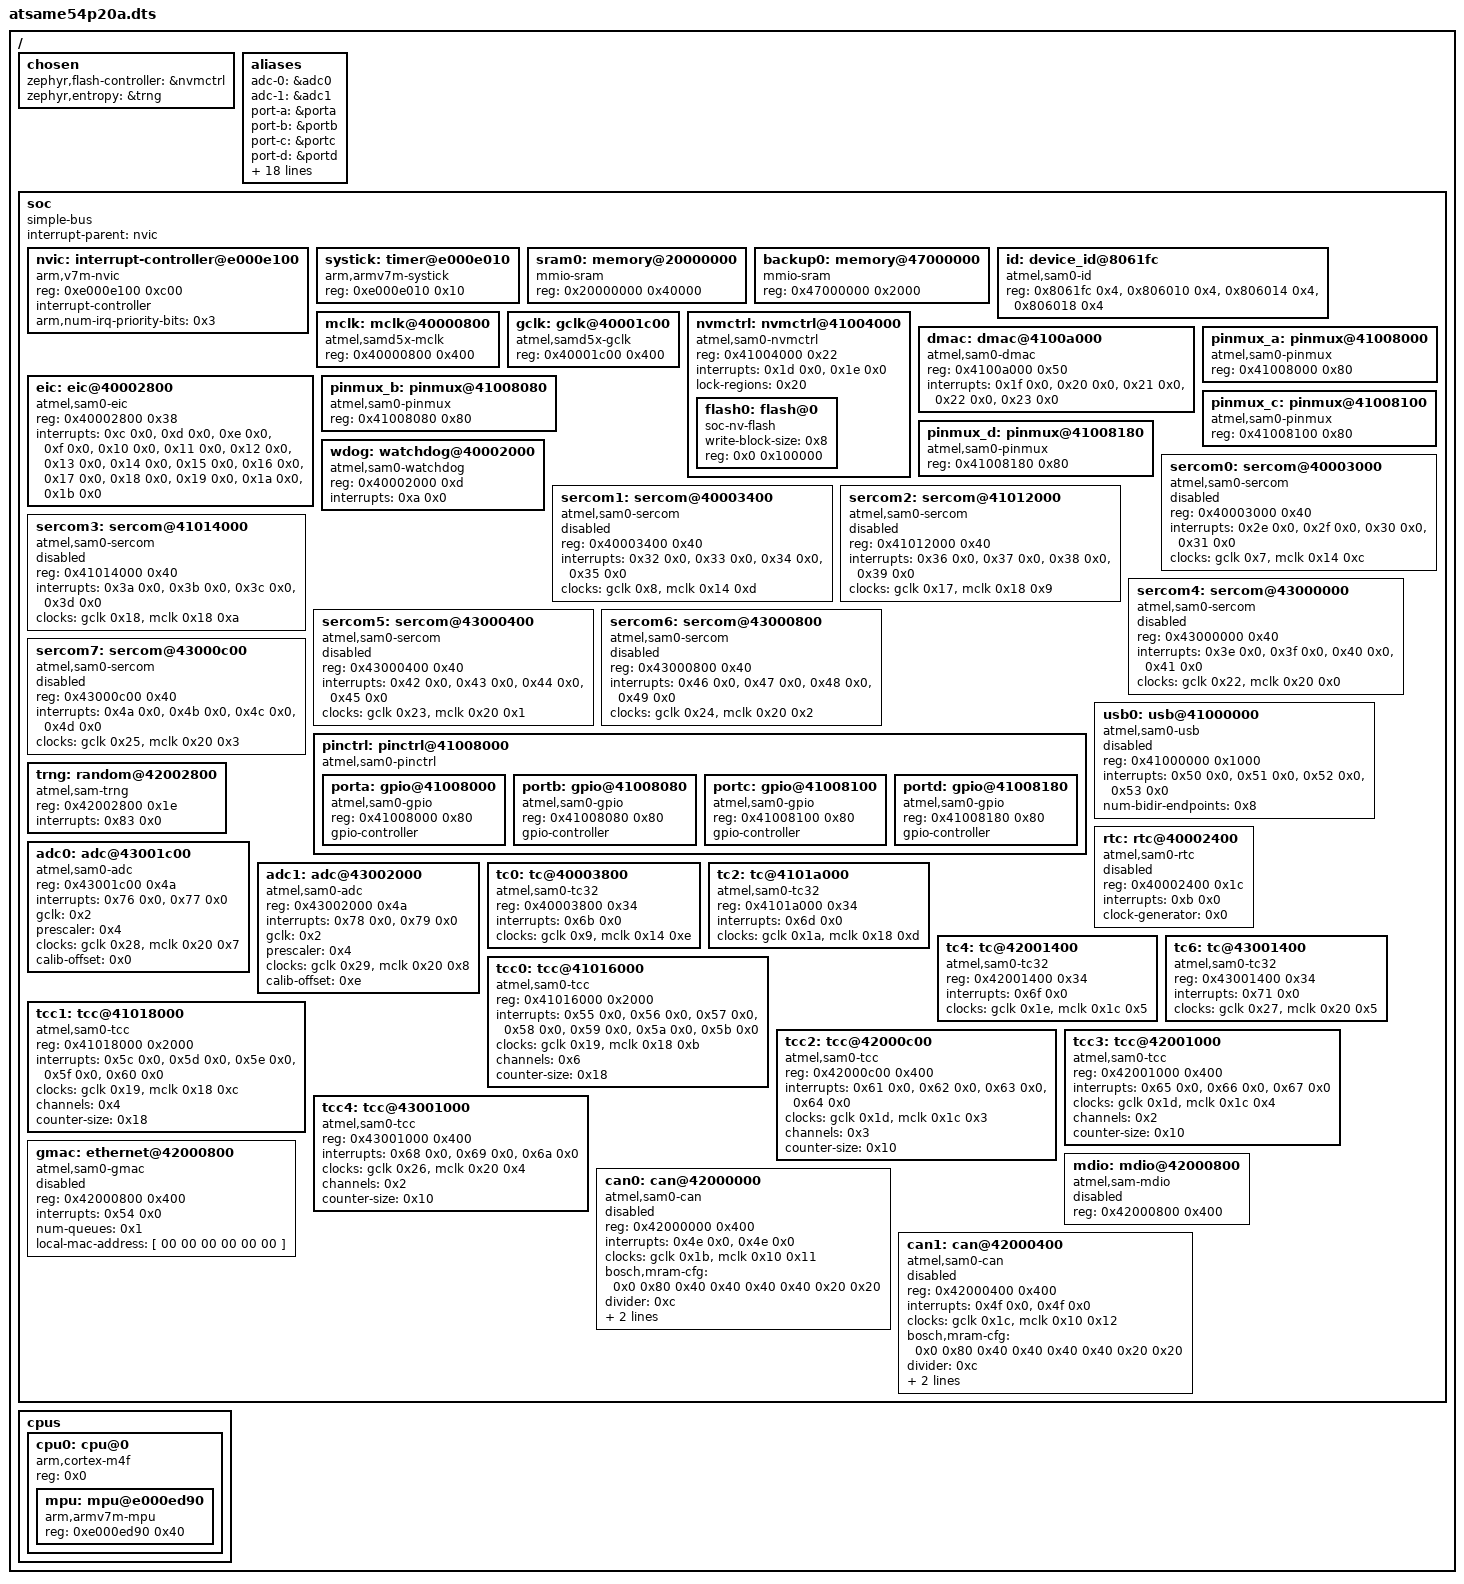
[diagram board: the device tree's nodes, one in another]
/dts-v1/;

/ {
	#address-cells = < 0x1 >;
	#size-cells = < 0x1 >;
	chosen {
		zephyr,flash-controller = &nvmctrl;
		zephyr,entropy = &trng;
	};
	aliases {
		adc-0 = &adc0;
		adc-1 = &adc1;
		port-a = &porta;
		port-b = &portb;
		port-c = &portc;
		port-d = &portd;
		sercom-0 = &sercom0;
		sercom-1 = &sercom1;
		sercom-2 = &sercom2;
		sercom-3 = &sercom3;
		sercom-4 = &sercom4;
		sercom-5 = &sercom5;
		sercom-6 = &sercom6;
		sercom-7 = &sercom7;
		tc-0 = &tc0;
		tc-2 = &tc2;
		tc-4 = &tc4;
		tc-6 = &tc6;
		tcc-0 = &tcc0;
		tcc-1 = &tcc1;
		tcc-2 = &tcc2;
		tcc-3 = &tcc3;
		tcc-4 = &tcc4;
		watchdog0 = &wdog;
	};
	soc {
		#address-cells = < 0x1 >;
		#size-cells = < 0x1 >;
		compatible = "simple-bus";
		interrupt-parent = < &nvic >;
		ranges;
		nvic: interrupt-controller@e000e100 {
			#address-cells = < 0x1 >;
			compatible = "arm,v7m-nvic";
			reg = < 0xe000e100 0xc00 >;
			interrupt-controller;
			#interrupt-cells = < 0x2 >;
			arm,num-irq-priority-bits = < 0x3 >;
			phandle = < 0x1 >;
		};
		systick: timer@e000e010 {
			compatible = "arm,armv7m-systick";
			reg = < 0xe000e010 0x10 >;
		};
		sram0: memory@20000000 {
			compatible = "mmio-sram";
			reg = < 0x20000000 0x40000 >;
		};
		backup0: memory@47000000 {
			compatible = "mmio-sram";
			reg = < 0x47000000 0x2000 >;
		};
		id: device_id@8061fc {
			compatible = "atmel,sam0-id";
			reg = < 0x8061fc 0x4 >, < 0x806010 0x4 >, < 0x806014 0x4 >, < 0x806018 0x4 >;
		};
		mclk: mclk@40000800 {
			compatible = "atmel,samd5x-mclk";
			reg = < 0x40000800 0x400 >;
			#clock-cells = < 0x2 >;
			phandle = < 0x3 >;
		};
		gclk: gclk@40001c00 {
			compatible = "atmel,samd5x-gclk";
			reg = < 0x40001c00 0x400 >;
			#clock-cells = < 0x1 >;
			phandle = < 0x2 >;
		};
		nvmctrl: nvmctrl@41004000 {
			compatible = "atmel,sam0-nvmctrl";
			reg = < 0x41004000 0x22 >;
			interrupts = < 0x1d 0x0 >, < 0x1e 0x0 >;
			lock-regions = < 0x20 >;
			#address-cells = < 0x1 >;
			#size-cells = < 0x1 >;
			flash0: flash@0 {
				compatible = "soc-nv-flash";
				write-block-size = < 0x8 >;
				reg = < 0x0 0x100000 >;
			};
		};
		dmac: dmac@4100a000 {
			compatible = "atmel,sam0-dmac";
			reg = < 0x4100a000 0x50 >;
			interrupts = < 0x1f 0x0 >, < 0x20 0x0 >, < 0x21 0x0 >, < 0x22 0x0 >, < 0x23 0x0 >;
			#dma-cells = < 0x2 >;
		};
		eic: eic@40002800 {
			compatible = "atmel,sam0-eic";
			reg = < 0x40002800 0x38 >;
			interrupts = < 0xc 0x0 >, < 0xd 0x0 >, < 0xe 0x0 >, < 0xf 0x0 >, < 0x10 0x0 >, < 0x11 0x0 >, < 0x12 0x0 >, < 0x13 0x0 >, < 0x14 0x0 >, < 0x15 0x0 >, < 0x16 0x0 >, < 0x17 0x0 >, < 0x18 0x0 >, < 0x19 0x0 >, < 0x1a 0x0 >, < 0x1b 0x0 >;
		};
		pinmux_a: pinmux@41008000 {
			compatible = "atmel,sam0-pinmux";
			reg = < 0x41008000 0x80 >;
		};
		pinmux_b: pinmux@41008080 {
			compatible = "atmel,sam0-pinmux";
			reg = < 0x41008080 0x80 >;
		};
		pinmux_c: pinmux@41008100 {
			compatible = "atmel,sam0-pinmux";
			reg = < 0x41008100 0x80 >;
		};
		pinmux_d: pinmux@41008180 {
			compatible = "atmel,sam0-pinmux";
			reg = < 0x41008180 0x80 >;
		};
		wdog: watchdog@40002000 {
			compatible = "atmel,sam0-watchdog";
			reg = < 0x40002000 0xd >;
			interrupts = < 0xa 0x0 >;
		};
		sercom0: sercom@40003000 {
			compatible = "atmel,sam0-sercom";
			reg = < 0x40003000 0x40 >;
			interrupts = < 0x2e 0x0 >, < 0x2f 0x0 >, < 0x30 0x0 >, < 0x31 0x0 >;
			status = "disabled";
			clocks = < &gclk 0x7 >, < &mclk 0x14 0xc >;
			clock-names = "GCLK", "MCLK";
		};
		sercom1: sercom@40003400 {
			compatible = "atmel,sam0-sercom";
			reg = < 0x40003400 0x40 >;
			interrupts = < 0x32 0x0 >, < 0x33 0x0 >, < 0x34 0x0 >, < 0x35 0x0 >;
			status = "disabled";
			clocks = < &gclk 0x8 >, < &mclk 0x14 0xd >;
			clock-names = "GCLK", "MCLK";
		};
		sercom2: sercom@41012000 {
			compatible = "atmel,sam0-sercom";
			reg = < 0x41012000 0x40 >;
			interrupts = < 0x36 0x0 >, < 0x37 0x0 >, < 0x38 0x0 >, < 0x39 0x0 >;
			status = "disabled";
			clocks = < &gclk 0x17 >, < &mclk 0x18 0x9 >;
			clock-names = "GCLK", "MCLK";
		};
		sercom3: sercom@41014000 {
			compatible = "atmel,sam0-sercom";
			reg = < 0x41014000 0x40 >;
			interrupts = < 0x3a 0x0 >, < 0x3b 0x0 >, < 0x3c 0x0 >, < 0x3d 0x0 >;
			status = "disabled";
			clocks = < &gclk 0x18 >, < &mclk 0x18 0xa >;
			clock-names = "GCLK", "MCLK";
		};
		sercom4: sercom@43000000 {
			compatible = "atmel,sam0-sercom";
			reg = < 0x43000000 0x40 >;
			interrupts = < 0x3e 0x0 >, < 0x3f 0x0 >, < 0x40 0x0 >, < 0x41 0x0 >;
			status = "disabled";
			clocks = < &gclk 0x22 >, < &mclk 0x20 0x0 >;
			clock-names = "GCLK", "MCLK";
		};
		sercom5: sercom@43000400 {
			compatible = "atmel,sam0-sercom";
			reg = < 0x43000400 0x40 >;
			interrupts = < 0x42 0x0 >, < 0x43 0x0 >, < 0x44 0x0 >, < 0x45 0x0 >;
			status = "disabled";
			clocks = < &gclk 0x23 >, < &mclk 0x20 0x1 >;
			clock-names = "GCLK", "MCLK";
		};
		sercom6: sercom@43000800 {
			compatible = "atmel,sam0-sercom";
			reg = < 0x43000800 0x40 >;
			interrupts = < 0x46 0x0 >, < 0x47 0x0 >, < 0x48 0x0 >, < 0x49 0x0 >;
			status = "disabled";
			clocks = < &gclk 0x24 >, < &mclk 0x20 0x2 >;
			clock-names = "GCLK", "MCLK";
		};
		sercom7: sercom@43000c00 {
			compatible = "atmel,sam0-sercom";
			reg = < 0x43000c00 0x40 >;
			interrupts = < 0x4a 0x0 >, < 0x4b 0x0 >, < 0x4c 0x0 >, < 0x4d 0x0 >;
			status = "disabled";
			clocks = < &gclk 0x25 >, < &mclk 0x20 0x3 >;
			clock-names = "GCLK", "MCLK";
		};
		pinctrl: pinctrl@41008000 {
			compatible = "atmel,sam0-pinctrl";
			#address-cells = < 0x1 >;
			#size-cells = < 0x1 >;
			ranges = < 0x41008000 0x41008000 0x200 >;
			porta: gpio@41008000 {
				compatible = "atmel,sam0-gpio";
				reg = < 0x41008000 0x80 >;
				gpio-controller;
				#gpio-cells = < 0x2 >;
				#atmel,pin-cells = < 0x2 >;
			};
			portb: gpio@41008080 {
				compatible = "atmel,sam0-gpio";
				reg = < 0x41008080 0x80 >;
				gpio-controller;
				#gpio-cells = < 0x2 >;
				#atmel,pin-cells = < 0x2 >;
			};
			portc: gpio@41008100 {
				compatible = "atmel,sam0-gpio";
				reg = < 0x41008100 0x80 >;
				gpio-controller;
				#gpio-cells = < 0x2 >;
				#atmel,pin-cells = < 0x2 >;
			};
			portd: gpio@41008180 {
				compatible = "atmel,sam0-gpio";
				reg = < 0x41008180 0x80 >;
				gpio-controller;
				#gpio-cells = < 0x2 >;
				#atmel,pin-cells = < 0x2 >;
			};
		};
		usb0: usb@41000000 {
			compatible = "atmel,sam0-usb";
			status = "disabled";
			reg = < 0x41000000 0x1000 >;
			interrupts = < 0x50 0x0 >, < 0x51 0x0 >, < 0x52 0x0 >, < 0x53 0x0 >;
			num-bidir-endpoints = < 0x8 >;
		};
		trng: random@42002800 {
			compatible = "atmel,sam-trng";
			reg = < 0x42002800 0x1e >;
			interrupts = < 0x83 0x0 >;
		};
		rtc: rtc@40002400 {
			compatible = "atmel,sam0-rtc";
			reg = < 0x40002400 0x1c >;
			interrupts = < 0xb 0x0 >;
			clock-generator = < 0x0 >;
			status = "disabled";
		};
		adc0: adc@43001c00 {
			compatible = "atmel,sam0-adc";
			reg = < 0x43001c00 0x4a >;
			interrupts = < 0x76 0x0 >, < 0x77 0x0 >;
			interrupt-names = "overrun", "resrdy";
			gclk = < 0x2 >;
			prescaler = < 0x4 >;
			#io-channel-cells = < 0x1 >;
			clocks = < &gclk 0x28 >, < &mclk 0x20 0x7 >;
			clock-names = "GCLK", "MCLK";
			calib-offset = < 0x0 >;
		};
		adc1: adc@43002000 {
			compatible = "atmel,sam0-adc";
			reg = < 0x43002000 0x4a >;
			interrupts = < 0x78 0x0 >, < 0x79 0x0 >;
			interrupt-names = "overrun", "resrdy";
			gclk = < 0x2 >;
			prescaler = < 0x4 >;
			#io-channel-cells = < 0x1 >;
			clocks = < &gclk 0x29 >, < &mclk 0x20 0x8 >;
			clock-names = "GCLK", "MCLK";
			calib-offset = < 0xe >;
		};
		tc0: tc@40003800 {
			compatible = "atmel,sam0-tc32";
			reg = < 0x40003800 0x34 >;
			interrupts = < 0x6b 0x0 >;
			clocks = < &gclk 0x9 >, < &mclk 0x14 0xe >;
			clock-names = "GCLK", "MCLK";
		};
		tc2: tc@4101a000 {
			compatible = "atmel,sam0-tc32";
			reg = < 0x4101a000 0x34 >;
			interrupts = < 0x6d 0x0 >;
			clocks = < &gclk 0x1a >, < &mclk 0x18 0xd >;
			clock-names = "GCLK", "MCLK";
		};
		tc4: tc@42001400 {
			compatible = "atmel,sam0-tc32";
			reg = < 0x42001400 0x34 >;
			interrupts = < 0x6f 0x0 >;
			clocks = < &gclk 0x1e >, < &mclk 0x1c 0x5 >;
			clock-names = "GCLK", "MCLK";
		};
		tc6: tc@43001400 {
			compatible = "atmel,sam0-tc32";
			reg = < 0x43001400 0x34 >;
			interrupts = < 0x71 0x0 >;
			clocks = < &gclk 0x27 >, < &mclk 0x20 0x5 >;
			clock-names = "GCLK", "MCLK";
		};
		tcc0: tcc@41016000 {
			compatible = "atmel,sam0-tcc";
			reg = < 0x41016000 0x2000 >;
			interrupts = < 0x55 0x0 >, < 0x56 0x0 >, < 0x57 0x0 >, < 0x58 0x0 >, < 0x59 0x0 >, < 0x5a 0x0 >, < 0x5b 0x0 >;
			clocks = < &gclk 0x19 >, < &mclk 0x18 0xb >;
			clock-names = "GCLK", "MCLK";
			channels = < 0x6 >;
			counter-size = < 0x18 >;
		};
		tcc1: tcc@41018000 {
			compatible = "atmel,sam0-tcc";
			reg = < 0x41018000 0x2000 >;
			interrupts = < 0x5c 0x0 >, < 0x5d 0x0 >, < 0x5e 0x0 >, < 0x5f 0x0 >, < 0x60 0x0 >;
			clocks = < &gclk 0x19 >, < &mclk 0x18 0xc >;
			clock-names = "GCLK", "MCLK";
			channels = < 0x4 >;
			counter-size = < 0x18 >;
		};
		tcc2: tcc@42000c00 {
			compatible = "atmel,sam0-tcc";
			reg = < 0x42000c00 0x400 >;
			interrupts = < 0x61 0x0 >, < 0x62 0x0 >, < 0x63 0x0 >, < 0x64 0x0 >;
			clocks = < &gclk 0x1d >, < &mclk 0x1c 0x3 >;
			clock-names = "GCLK", "MCLK";
			channels = < 0x3 >;
			counter-size = < 0x10 >;
		};
		tcc3: tcc@42001000 {
			compatible = "atmel,sam0-tcc";
			reg = < 0x42001000 0x400 >;
			interrupts = < 0x65 0x0 >, < 0x66 0x0 >, < 0x67 0x0 >;
			clocks = < &gclk 0x1d >, < &mclk 0x1c 0x4 >;
			clock-names = "GCLK", "MCLK";
			channels = < 0x2 >;
			counter-size = < 0x10 >;
		};
		tcc4: tcc@43001000 {
			compatible = "atmel,sam0-tcc";
			reg = < 0x43001000 0x400 >;
			interrupts = < 0x68 0x0 >, < 0x69 0x0 >, < 0x6a 0x0 >;
			clocks = < &gclk 0x26 >, < &mclk 0x20 0x4 >;
			clock-names = "GCLK", "MCLK";
			channels = < 0x2 >;
			counter-size = < 0x10 >;
		};
		gmac: ethernet@42000800 {
			compatible = "atmel,sam0-gmac";
			reg = < 0x42000800 0x400 >;
			interrupts = < 0x54 0x0 >;
			interrupt-names = "gmac";
			num-queues = < 0x1 >;
			local-mac-address = [ 00 00 00 00 00 00 ];
			status = "disabled";
		};
		mdio: mdio@42000800 {
			compatible = "atmel,sam-mdio";
			reg = < 0x42000800 0x400 >;
			status = "disabled";
			#address-cells = < 0x1 >;
			#size-cells = < 0x0 >;
		};
		can0: can@42000000 {
			compatible = "atmel,sam0-can";
			reg = < 0x42000000 0x400 >;
			interrupts = < 0x4e 0x0 >, < 0x4e 0x0 >;
			interrupt-names = "int0", "int1";
			clocks = < &gclk 0x1b >, < &mclk 0x10 0x11 >;
			clock-names = "GCLK", "MCLK";
			bosch,mram-cfg = < 0x0 0x80 0x40 0x40 0x40 0x40 0x20 0x20 >;
			divider = < 0xc >;
			sample-point = < 0x36b >;
			sample-point-data = < 0x36b >;
			status = "disabled";
		};
		can1: can@42000400 {
			compatible = "atmel,sam0-can";
			reg = < 0x42000400 0x400 >;
			interrupts = < 0x4f 0x0 >, < 0x4f 0x0 >;
			interrupt-names = "int0", "int1";
			clocks = < &gclk 0x1c >, < &mclk 0x10 0x12 >;
			clock-names = "GCLK", "MCLK";
			bosch,mram-cfg = < 0x0 0x80 0x40 0x40 0x40 0x40 0x20 0x20 >;
			divider = < 0xc >;
			sample-point = < 0x36b >;
			sample-point-data = < 0x36b >;
			status = "disabled";
		};
	};
	cpus {
		#address-cells = < 0x1 >;
		#size-cells = < 0x0 >;
		cpu0: cpu@0 {
			device_type = "cpu";
			compatible = "arm,cortex-m4f";
			reg = < 0x0 >;
			#address-cells = < 0x1 >;
			#size-cells = < 0x1 >;
			mpu: mpu@e000ed90 {
				compatible = "arm,armv7m-mpu";
				reg = < 0xe000ed90 0x40 >;
			};
		};
	};
};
